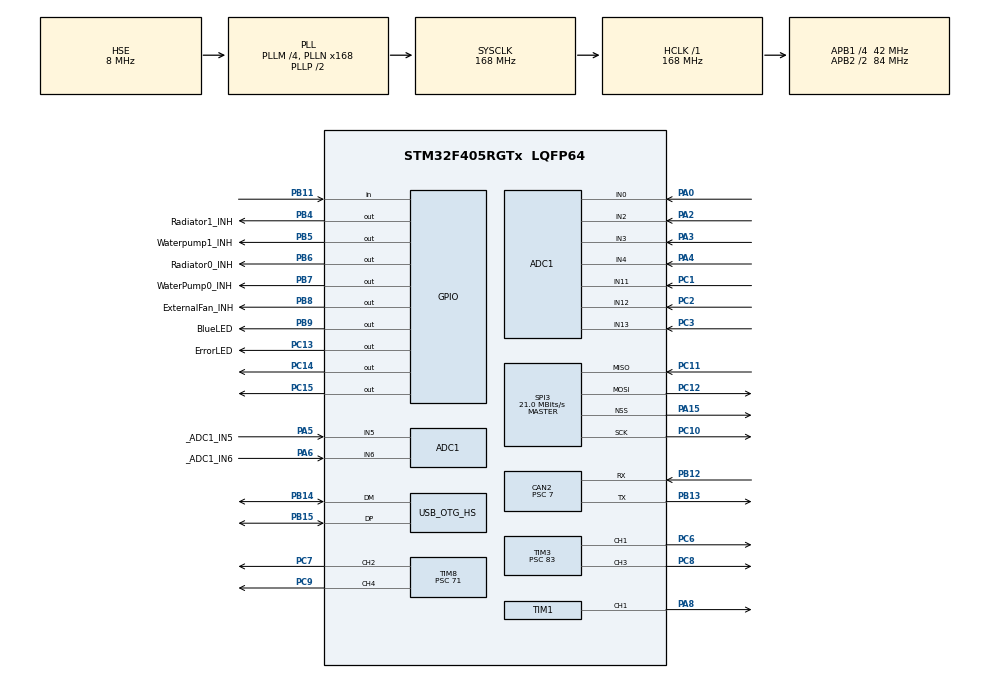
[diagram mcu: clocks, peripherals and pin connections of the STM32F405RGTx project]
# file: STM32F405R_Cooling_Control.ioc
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ADC1.Channel-1\#ChannelRegularConversion=ADC_CHANNEL_0
ADC1.Channel-10\#ChannelRegularConversion=ADC_CHANNEL_6
ADC1.Channel-2\#ChannelRegularConversion=ADC_CHANNEL_2
ADC1.Channel-3\#ChannelRegularConversion=ADC_CHANNEL_3
ADC1.Channel-4\#ChannelRegularConversion=ADC_CHANNEL_4
ADC1.Channel-5\#ChannelRegularConversion=ADC_CHANNEL_13
ADC1.Channel-6\#ChannelRegularConversion=ADC_CHANNEL_12
ADC1.Channel-7\#ChannelRegularConversion=ADC_CHANNEL_11
ADC1.Channel-9\#ChannelRegularConversion=ADC_CHANNEL_5
ADC1.ClockPrescaler=ADC_CLOCK_SYNC_PCLK_DIV4
ADC1.ContinuousConvMode=ENABLE
ADC1.DMAContinuousRequests=ENABLE
ADC1.NbrOfConversion=9
ADC1.NbrOfConversionFlag=1
ADC1.Rank-1\#ChannelRegularConversion=1
ADC1.Rank-10\#ChannelRegularConversion=9
ADC1.Rank-2\#ChannelRegularConversion=2
ADC1.Rank-3\#ChannelRegularConversion=3
ADC1.Rank-4\#ChannelRegularConversion=4
ADC1.Rank-5\#ChannelRegularConversion=5
ADC1.Rank-6\#ChannelRegularConversion=6
ADC1.Rank-7\#ChannelRegularConversion=7
ADC1.Rank-9\#ChannelRegularConversion=8
ADC1.SamplingTime-1\#ChannelRegularConversion=ADC_SAMPLETIME_3CYCLES
ADC1.SamplingTime-10\#ChannelRegularConversion=ADC_SAMPLETIME_3CYCLES
ADC1.SamplingTime-2\#ChannelRegularConversion=ADC_SAMPLETIME_3CYCLES
ADC1.SamplingTime-3\#ChannelRegularConversion=ADC_SAMPLETIME_3CYCLES
ADC1.SamplingTime-4\#ChannelRegularConversion=ADC_SAMPLETIME_3CYCLES
ADC1.SamplingTime-5\#ChannelRegularConversion=ADC_SAMPLETIME_3CYCLES
ADC1.SamplingTime-6\#ChannelRegularConversion=ADC_SAMPLETIME_3CYCLES
ADC1.SamplingTime-7\#ChannelRegularConversion=ADC_SAMPLETIME_3CYCLES
ADC1.SamplingTime-9\#ChannelRegularConversion=ADC_SAMPLETIME_3CYCLES
ADC1.master=1
CAN2.BS1=CAN_BS1_4TQ
CAN2.CalculateBaudRate=999999
CAN2.CalculateTimeBit=1000
CAN2.CalculateTimeQuantum=166.66666666666669
CAN2.Prescaler=7
Dma.ADC1.0.Direction=DMA_PERIPH_TO_MEMORY
Dma.ADC1.0.FIFOMode=DMA_FIFOMODE_DISABLE
Dma.ADC1.0.Instance=DMA2_Stream0
Dma.ADC1.0.MemDataAlignment=DMA_MDATAALIGN_WORD
Dma.ADC1.0.MemInc=DMA_MINC_ENABLE
Dma.ADC1.0.Mode=DMA_CIRCULAR
Dma.ADC1.0.PeriphDataAlignment=DMA_PDATAALIGN_WORD
Dma.ADC1.0.PeriphInc=DMA_PINC_DISABLE
Dma.ADC1.0.Priority=DMA_PRIORITY_LOW
Dma.Request0=ADC1
Mcu.Family=STM32F4
Mcu.Name=STM32F405RGTx
Mcu.Package=LQFP64
NVIC.CAN2_RX0_IRQn=true\:0\:0\:false\:false\:true\:true\:true\:true
NVIC.CAN2_RX1_IRQn=true\:0\:0\:false\:false\:true\:true\:true\:true
NVIC.DMA2_Stream0_IRQn=true\:0\:0\:false\:false\:true\:false\:true\:true
NVIC.PriorityGroup=NVIC_PRIORITYGROUP_4
PA0-WKUP.Signal=ADCx_IN0
PA13.Mode=Trace_Asynchronous_SW
PA13.Signal=SYS_JTMS-SWDIO
PA14.Mode=Trace_Asynchronous_SW
PA14.Signal=SYS_JTCK-SWCLK
PA15.Mode=NSS_Signal_Hard_Output
PA15.Signal=SPI3_NSS
PA2.Signal=ADCx_IN2
PA3.Signal=ADCx_IN3
PA4.Signal=ADCx_IN4
PA5.GPIO_Label=_ADC1_IN5
PA5.Signal=ADCx_IN5
PA6.GPIO_Label=_ADC1_IN6
PA6.Signal=ADCx_IN6
PA8.Signal=S_TIM1_CH1
PB11.Signal=GPIO_Input
PB12.Mode=CAN_Activate
PB12.Signal=CAN2_RX
PB13.Mode=CAN_Activate
PB13.Signal=CAN2_TX
PB14.Mode=Device_Only_FS
PB14.Signal=USB_OTG_HS_DM
PB15.Mode=Device_Only_FS
PB15.Signal=USB_OTG_HS_DP
PB3.Mode=Trace_Asynchronous_SW
PB3.Signal=SYS_JTDO-SWO
PB4.GPIO_Label=Radiator1_INH
PB4.Signal=GPIO_Output
PB5.GPIO_Label=Waterpump1_INH
PB5.Signal=GPIO_Output
PB6.GPIO_Label=Radiator0_INH
PB6.Signal=GPIO_Output
PB7.GPIO_Label=WaterPump0_INH
PB7.Signal=GPIO_Output
PB8.GPIO_Label=ExternalFan_INH
PB8.Signal=GPIO_Output
PB9.GPIO_Label=BlueLED
PB9.Signal=GPIO_Output
PC1.Signal=ADCx_IN11
PC10.Mode=Full_Duplex_Master
PC10.Signal=SPI3_SCK
PC11.Mode=Full_Duplex_Master
PC11.Signal=SPI3_MISO
PC12.Mode=Full_Duplex_Master
PC12.Signal=SPI3_MOSI
PC13-ANTI_TAMP.GPIO_Label=ErrorLED
PC13-ANTI_TAMP.Signal=GPIO_Output
PC14-OSC32_IN.Signal=GPIO_Output
PC15-OSC32_OUT.Signal=GPIO_Output
PC2.Signal=ADCx_IN12
PC3.Signal=ADCx_IN13
PC6.Signal=S_TIM3_CH1
PC7.Signal=S_TIM8_CH2
PC8.Signal=S_TIM3_CH3
PC9.Signal=S_TIM8_CH4
PH0-OSC_IN.Mode=HSE-External-Oscillator
PH0-OSC_IN.Signal=RCC_OSC_IN
PH1-OSC_OUT.Mode=HSE-External-Oscillator
PH1-OSC_OUT.Signal=RCC_OSC_OUT
ProjectManager.HeapSize=0x200
ProjectManager.StackSize=0x400
ProjectManager.TargetToolchain=STM32CubeIDE
RCC.48MHZClocksFreq_Value=48000000
RCC.AHBFreq_Value=168000000
RCC.APB1CLKDivider=RCC_HCLK_DIV4
RCC.APB1Freq_Value=42000000
RCC.APB1TimFreq_Value=84000000
RCC.APB2CLKDivider=RCC_HCLK_DIV2
RCC.APB2Freq_Value=84000000
RCC.APB2TimFreq_Value=168000000
RCC.CortexFreq_Value=168000000
RCC.EnbaleCSS=true
RCC.HCLKFreq_Value=168000000
RCC.HSE_VALUE=8000000
RCC.HSI_VALUE=16000000
RCC.LSE_VALUE=32768
RCC.PLLM=4
RCC.PLLN=168
RCC.PLLQ=7
RCC.RCC_RTC_Clock_Source=RCC_RTCCLKSOURCE_LSE
RCC.RCC_RTC_Clock_SourceVirtual=RCC_RTCCLKSOURCE_LSE
RCC.RCC_RTC_Clock_Source_FROM_HSE=RCC_RTCCLKSOURCE_HSE_DIV31
RCC.SYSCLKFreq_VALUE=168000000
RCC.SYSCLKSource=RCC_SYSCLKSOURCE_PLLCLK
RCC.VCOOutputFreq_Value=336000000
SH.ADCx_IN0.0=ADC1_IN0,IN0
SH.ADCx_IN11.0=ADC1_IN11,IN11
SH.ADCx_IN12.0=ADC1_IN12,IN12
SH.ADCx_IN13.0=ADC1_IN13,IN13
SH.ADCx_IN2.0=ADC1_IN2,IN2
SH.ADCx_IN3.0=ADC1_IN3,IN3
SH.ADCx_IN4.0=ADC1_IN4,IN4
SH.ADCx_IN5.0=ADC1_IN5,IN5
SH.ADCx_IN6.0=ADC1_IN6,IN6
SH.S_TIM1_CH1.0=TIM1_CH1,PWM Generation1 CH1
SH.S_TIM3_CH1.0=TIM3_CH1,PWM Generation1 CH1
SH.S_TIM3_CH3.0=TIM3_CH3,PWM Generation3 CH3
SH.S_TIM8_CH2.0=TIM8_CH2,PWM Generation2 CH2
SH.S_TIM8_CH4.0=TIM8_CH4,PWM Generation4 CH4
SPI3.BaudRatePrescaler=SPI_BAUDRATEPRESCALER_2
SPI3.CalculateBaudRate=21.0 MBits/s
SPI3.Direction=SPI_DIRECTION_2LINES
SPI3.Mode=SPI_MODE_MASTER
SPI3.VirtualNSS=VM_NSSHARD
SPI3.VirtualType=VM_MASTER
TIM1.Channel-PWM\ Generation1\ CH1=TIM_CHANNEL_1
TIM1.CounterMode=TIM_COUNTERMODE_UP
TIM1.Period=99
TIM1.Prescaler=71
TIM1.Pulse-PWM\ Generation1\ CH1=99
TIM3.Channel-PWM\ Generation1\ CH1=TIM_CHANNEL_1
TIM3.Channel-PWM\ Generation3\ CH3=TIM_CHANNEL_3
TIM3.Period=99
TIM3.Prescaler=83
TIM3.Pulse-PWM\ Generation1\ CH1=99
TIM3.Pulse-PWM\ Generation3\ CH3=99
TIM8.Channel-PWM\ Generation2\ CH2=TIM_CHANNEL_2
TIM8.Channel-PWM\ Generation4\ CH4=TIM_CHANNEL_4
TIM8.Period=99
TIM8.Prescaler=71
USB_OTG_HS.VirtualMode-Device_Only_FS=Device_Only_FS
VP_CRC_VS_CRC.Mode=CRC_Activate
VP_TIM5_VS_ClockSourceITR.Mode=TriggerSource_ITR0
board=custom

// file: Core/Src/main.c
/* USER CODE BEGIN Header */
/**
  ******************************************************************************
  * @file           : main.c
  * @brief          : Main program body
  ******************************************************************************
  * @attention
  *
  * <h2><center>&copy; Copyright (c) 2021 STMicroelectronics.
  * All rights reserved.</center></h2>
  *
  * This software component is licensed by ST under BSD 3-Clause license,
  * the "License"; You may not use this file except in compliance with the
  * License. You may obtain a copy of the License at:
  *                        opensource.org/licenses/BSD-3-Clause
  *
  ******************************************************************************
  */
/* USER CODE END Header */
#include "main.h"
#include "adc.h"
#include "can.h"
#include "crc.h"
#include "dma.h"
#include "spi.h"
#include "tim.h"
#include "usb_otg.h"
#include "gpio.h"

void SystemClock_Config(void);

int main(void)
{

  /* MCU Configuration--------------------------------------------------------*/

  /* Reset of all peripherals, Initializes the Flash interface and the Systick. */
  HAL_Init();

  /* Configure the system clock */
  SystemClock_Config();

  /* Initialize all configured peripherals */
  MX_GPIO_Init();
  MX_DMA_Init();
  MX_ADC1_Init();
  MX_CAN2_Init();
  MX_SPI3_Init();
  MX_TIM1_Init();
  MX_CRC_Init();
  MX_TIM8_Init();
  MX_USB_OTG_HS_PCD_Init();
  MX_TIM5_Init();
  MX_TIM3_Init();
  /* USER CODE BEGIN 2 */
  GAS_Scheduler_init();
  /* USER CODE END 2 */

  /* Infinite loop */
  while (1)
  {

    /* USER CODE BEGIN 3 */
	  GAS_Scheduler();
  }
  /* USER CODE END 3 */
}

void SystemClock_Config(void)
{
  RCC_OscInitTypeDef RCC_OscInitStruct = {0};
  RCC_ClkInitTypeDef RCC_ClkInitStruct = {0};

  /** Configure the main internal regulator output voltage
  */
  __HAL_RCC_PWR_CLK_ENABLE();
  __HAL_PWR_VOLTAGESCALING_CONFIG(PWR_REGULATOR_VOLTAGE_SCALE1);
  /** Initializes the RCC Oscillators according to the specified parameters
  * in the RCC_OscInitTypeDef structure.
  */
  RCC_OscInitStruct.OscillatorType = RCC_OSCILLATORTYPE_HSE;
  RCC_OscInitStruct.HSEState = RCC_HSE_ON;
  RCC_OscInitStruct.PLL.PLLState = RCC_PLL_ON;
  RCC_OscInitStruct.PLL.PLLSource = RCC_PLLSOURCE_HSE;
  RCC_OscInitStruct.PLL.PLLM = 4;
  RCC_OscInitStruct.PLL.PLLN = 168;
  RCC_OscInitStruct.PLL.PLLP = RCC_PLLP_DIV2;
  RCC_OscInitStruct.PLL.PLLQ = 7;
  if (HAL_RCC_OscConfig(&RCC_OscInitStruct) != HAL_OK)
  {
    Error_Handler();
  }
  /** Initializes the CPU, AHB and APB buses clocks
  */
  RCC_ClkInitStruct.ClockType = RCC_CLOCKTYPE_HCLK|RCC_CLOCKTYPE_SYSCLK
                              |RCC_CLOCKTYPE_PCLK1|RCC_CLOCKTYPE_PCLK2;
  RCC_ClkInitStruct.SYSCLKSource = RCC_SYSCLKSOURCE_PLLCLK;
  RCC_ClkInitStruct.AHBCLKDivider = RCC_SYSCLK_DIV1;
  RCC_ClkInitStruct.APB1CLKDivider = RCC_HCLK_DIV4;
  RCC_ClkInitStruct.APB2CLKDivider = RCC_HCLK_DIV2;

  if (HAL_RCC_ClockConfig(&RCC_ClkInitStruct, FLASH_LATENCY_5) != HAL_OK)
  {
    Error_Handler();
  }
  /** Enables the Clock Security System
  */
  HAL_RCC_EnableCSS();
}

void Error_Handler(void)
{
  /* USER CODE BEGIN Error_Handler_Debug */
  /* User can add his own implementation to report the HAL error return state */
  __disable_irq();
  while (1)
  {
	HAL_GPIO_WritePin(GPIOC,ErrorLED_Pin, GPIO_PIN_SET);
  }
  /* USER CODE END Error_Handler_Debug */
}

/************************ (C) COPYRIGHT STMicroelectronics *****END OF FILE****/
